# MSS_CTRL register map
Vendor: Texas Instruments
Registers are 32-bit, read-write, no defined reset value unless marked. A register's access mark holds for its fields unless they carry their own. Offsets are as the file gives them; [hi:lo] are bit positions; {n}, {i} and the like mark numbered series; 'fields as' and 'values as' point back to an identical list; <NAME> marks a mode.

## MSS_CTRL (part 2 of 3)
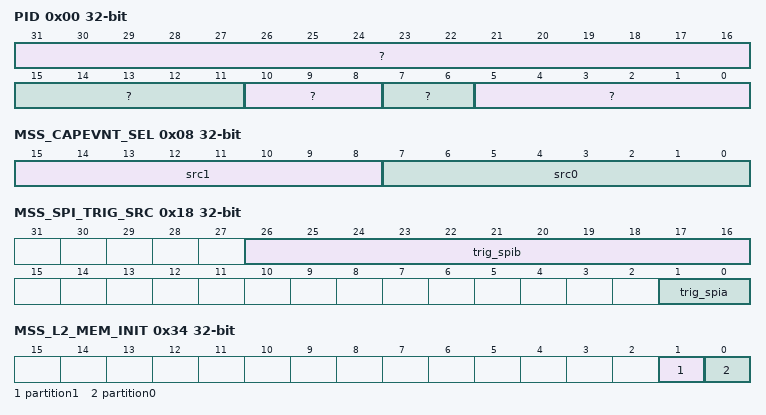
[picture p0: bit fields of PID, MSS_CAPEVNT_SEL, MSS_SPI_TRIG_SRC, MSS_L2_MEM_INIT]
0x00 PID ro
  [31:16] ?, [15:11] ?, [10:8] ?, [7:6] ?, [5:0] ?
0x04 MSS_SW_INT
  [4:0] pulse — write pulse bit field:Write_pulse bit field: writing 1'b1 to each bit will trigger MSS_SW_INT<0-4> respectively to CR5A/B.
0x08 MSS_CAPEVNT_SEL
  [15:8] src1 — Writing a value 'N' will select Nth interrupt from CR5A/B interrupt mapping to trigger CAP-EVENT1 to all MSS_RTIs. Example: writing 8'h0A will select 10th interrupt to trigger CAP-EVENT1 to all MSS_RTIs. (which is MSS_RTIB_INT1)
  [7:0] src0 — Writing a value 'N' will select Nth interrupt from CR5A/B interrupt mapping to trigger CAP-EVENT0 to all MSS_RTIs. Example: writing 8'h0A will select 10th interrupt to trigger CAP-EVENT0 to all MSS_RTIs. (which is MSS_RTIB_INT1)
0x0C MSS_DMA_REQ_SEL
  [31:0] select — Reserved for R&D. Do not touch
0x10 MSS_DMA1_REQ_SEL
  [31:0] select — Reserved for R&D. Do not touch
0x14 MSS_IRQ_REQ_SEL
  [31:0] select — Reserved for R&D. Do not touch
0x18 MSS_SPI_TRIG_SRC
  [26:16] trig_spib — Writing 1'b1 to each bit will trigger MSS_SPIB Trigger<0-10> respectively
  [1:0] trig_spia — Writing 1'b1 to each bit will trigger MSS_SPIA Trigger<0-1> respectively
0x1C MSS_ATCM_MEM_INIT
  [0] mem_init — write pulse bit field:Write_pulse bit field: Writing 1'b1 will start initializing the ATCM banks of CR5A/B. Value in each row is initialized to 0x0C_0000_0000
0x20 MSS_ATCM_MEM_INIT_DONE
  [0] mem_init_done — Rising Edge Capture reg (write 1 to clear): This field will be high once initialization of ATCM banks is finished. Writing '1' would clear the bit.
0x24 MSS_ATCM_MEM_INIT_STATUS ro
  [0] mem_status — 1'b0: No initialization is happening for ATCM banks of CR5A/B 1'b1: Initialization is in progress for ATCM banks of CR5A/B
0x28 MSS_BTCM_MEM_INIT
  [0] mem_init — write pulse bit field:Write_pulse bit field: Writing 1'b1 will start initializing the B0/1TCM banks of CR5A/B
0x2C MSS_BTCM_MEM_INIT_DONE
  [0] mem_init_done — Rising Edge Capture reg (write 1 to clear): This field will be high once initialization of B0/1TCM banks is finished. Writing '1' would clear the bit.
0x30 MSS_BTCM_MEM_INIT_STATUS ro
  [0] mem_status — 1'b0: No initialization is happening for B0/1TCM banks of CR5A/B 1'b1: Initialization is in progress for B0/1TCM banks of CR5A/B
0x34 MSS_L2_MEM_INIT
  [1] partition1 — write pulse bit field:Write_pulse bit field: Writing 1'b1 will start initializing the L2 Bank1. Value in each row is initialized to 0x0
  [0] partition0 — write pulse bit field:Write_pulse bit field: Writing 1'b1 will start initializing the L2 Bank0. Value in each row is initialized to 0x0
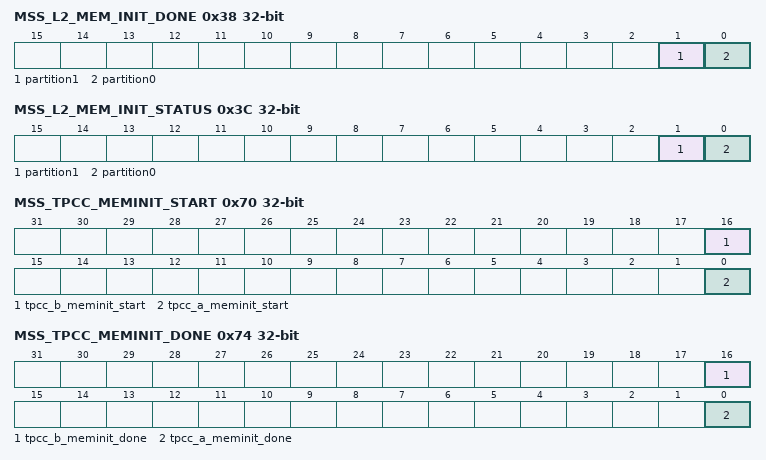
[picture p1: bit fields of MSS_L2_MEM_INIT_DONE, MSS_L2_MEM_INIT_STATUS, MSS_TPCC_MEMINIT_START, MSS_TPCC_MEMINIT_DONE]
0x38 MSS_L2_MEM_INIT_DONE
  [1] partition1 — Rising Edge Capture reg (write 1 to clear): This field will be high once intialization of L2 bank1 is finished. Writing '1' would clear the bit
  [0] partition0 — Rising Edge Capture reg (write 1 to clear): This field will be high once intialization of L2 bank0 is finished. Writing '1' would clear the bit
0x3C MSS_L2_MEM_INIT_STATUS ro
  [1] partition1 — 1'b0: No initialization is happening for L2 bank1 1'b1: Initialization is in progress for L2 bank1
  [0] partition0 — 1'b0: No initialization is happening for L2 bank0 1'b1: Initialization is in progress for L2 bank0
0x40 MSS_MAILBOX_MEM_INIT
  [0] mem0_init — write pulse bit field:Write_pulse bit field: Writing 1'b1 will start initializing the MSS_MBOX. Value in each row is initialized to 0x0
0x44 MSS_MAIlBOX_MEM_INIT_DONE
  [0] mem0_done — Rising Edge Capture reg (write 1 to clear): This field will be high once intialization of MSS_MBOX is finished. Writing '1' would clear the bit
0x48 MSS_MAILBOX_MEM_INIT_STATUS ro
  [0] mem0_status — 1'b0: No initialization is happening for MSS_MBOX 1'b1: Initialization is in progress for MSS_MBOX
0x4C MSS_RETRAM_MEM_INIT
  [0] mem0_init — write pulse bit field:Write_pulse bit field: Writing 1'b1 will start initializing the MSS_RETRAM. Value in each row is initialized to 0x0
0x50 MSS_RETRAM_MEM_INIT_DONE
  [0] mem0_done — Rising Edge Capture reg (write 1 to clear): This field will be high once intialization of MSS_RETRAM is finished. Writing '1' would clear the bit
0x54 MSS_RETRAM_MEM_INIT_STATUS ro
  [0] mem0_status — 1'b0: No initialization is happening for MSS_RETRAM 1'b1: Initialization is in progress for MSS_RETRAM
0x58 MSS_SPIA_MEM_INIT
  [0] mem0_init — write pulse bit field:Write_pulse bit field: Writing 1'b1 will start initializing the MSS_SPIA. Value in each row is initialized to 0x0
0x5C MSS_SPIA_MEM_INIT_DONE
  [0] mem0_done — Rising Edge Capture reg (write 1 to clear): This field will be high once intialization of MSS_SPIA is finished. Writing '1' would clear the bit
0x60 MSS_SPIA_MEM_INIT_STATUS ro
  [0] mem0_status — 1'b0: No initialization is happening for MSS_SPIA 1'b1: Initialization is in progress for MSS_SPIA
0x64 MSS_SPIB_MEM_INIT
  [0] mem0_init — write pulse bit field:Write_pulse bit field: Writing 1'b1 will start initializing the MSS_SPIB. Value in each row is initialized to 0x0
0x68 MSS_SPIB_MEM_INIT_DONE
  [0] mem0_done — Rising Edge Capture reg (write 1 to clear): This field will be high once intialization of MSS_SPIB is finished. Writing '1' would clear the bit
0x6C MSS_SPIB_MEM_INIT_STATUS ro
  [0] mem0_status — 1'b0: No initialization is happening for MSS_SPIB 1'b1: Initialization is in progress for MSS_SPIB
0x70 MSS_TPCC_MEMINIT_START
  [16] tpcc_b_meminit_start — write pulse bit field:Write_pulse bit field: Writing 1'b1 will start initializing the MSS_TPCCB
  [0] tpcc_a_meminit_start — write pulse bit field:Write_pulse bit field: Writing 1'b1 will start initializing the MSS_TPCCA
0x74 MSS_TPCC_MEMINIT_DONE
  [16] tpcc_b_meminit_done — Rising Edge Capture reg (write 1 to clear): This field will be high once intialization of MSS_TPCCB is finished. Writing '1' would clear the bit
  [0] tpcc_a_meminit_done — Rising Edge Capture reg (write 1 to clear): This field will be high once intialization of MSS_TPCCA is finished. Writing '1' would clear the bit
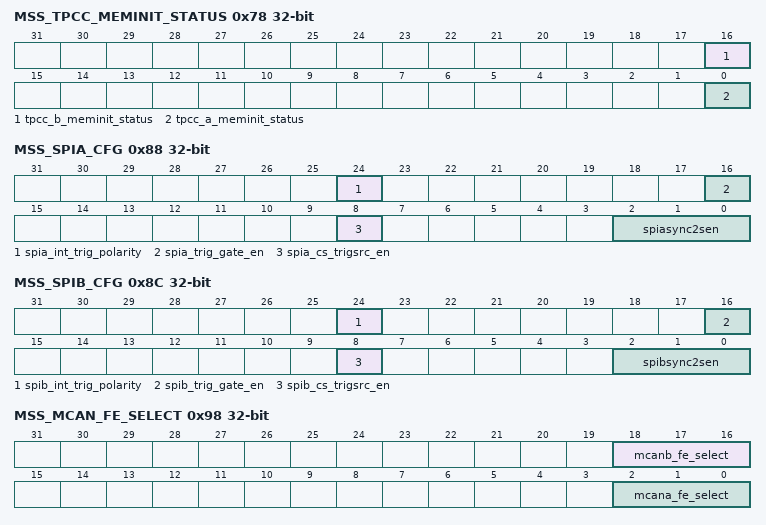
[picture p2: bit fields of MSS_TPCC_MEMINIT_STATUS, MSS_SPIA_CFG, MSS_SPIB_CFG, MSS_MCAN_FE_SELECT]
0x78 MSS_TPCC_MEMINIT_STATUS ro
  [16] tpcc_b_meminit_status — 1'b0: No initialization is happening for MSS_TPCCA 1'b1: Initialization is in progress for MSS_TPCCB
  [0] tpcc_a_meminit_status — 1'b0: No initialization is happening for MSS_TPCCA 1'b1: Initialization is in progress for MSS_TPCCB
0x7C MSS_GPADC_MEM_INIT
  [0] mem0_init — write pulse bit field:Write_pulse bit field: Writing 1'b1 will start initializing the MSS_GPADC_DATA_MEM. Value in each row is initialized to 0x00_0000_03FF
0x80 MSS_GPADC_MEM_INIT_DONE
  [0] mem0_done — Rising Edge Capture reg (write 1 to clear): This field will be high once intialization of MSS_GPADC_DATA_MEM is finished. Writing '1' would clear the bit
0x84 MSS_GPADC_MEM_INIT_STATUS ro
  [0] mem0_status — 1'b0: No initialization is happening for MSS_GPADC_DATA_MEM 1'b1: Initialization is in progress for MSS_GPADC_DATA_MEM
0x88 MSS_SPIA_CFG
  [24] spia_int_trig_polarity — SPIA trigger source polarity select. 0 - Polarity 0, 1 -Polarity 1
  [16] spia_trig_gate_en — When set the TRIGGER s are un-gated only when chip-select is active
  [8] spia_cs_trigsrc_en — MIBSPIB CS Trigger SRC enable 1 : Use CS as trigger source
  [2:0] spiasync2sen — Donot touch the field. Used as Tie-off for IP-config.
0x8C MSS_SPIB_CFG
  [24] spib_int_trig_polarity — SPIB trigger source polarity select. 0 - Polarity 0, 1 -Polarity 1
  [16] spib_trig_gate_en — When set the TRIGGER s are un-gated only when chip-select is active
  [8] spib_cs_trigsrc_en — MIBSPIB CS Trigger SRC enable 1 : Use CS as trigger source
  [2:0] spibsync2sen — Donot touch the field. Used as Tie-off for IP-config.
0x90 MSS_EPWM_CFG
  [31:0] epwm_config — bit0: SW syncin for EPWM1 bit1: SW syncin for EPWM2 bit2: SW syncin for EPWM3 bit8:9 : select bits for EPWM1 '0' : external syncin '1' : reserved '2' : sw syncin '3' : reserved bit10:11 : select bits for EPWM2 '0' : external syncin '1' : chained from EPWM1 '2' : sw syncin '3' : reserved bit12:13 : select bits for EPWM3 '0' : external syncin '1' : chained from EPWM2 '2' : sw syncin '3' : reserved bit24:TBCLKEN for EPWM1 bit25:TBCLKEN for EPWM2 bit26:TBCLKEN for EPWM3
0x94 MSS_GIO_CFG
  [31:0] gio_config — bit0 : writing '1' will slect negedge for pulse generation of GIO_PAD_INT0 to IRQ bit1 : writing '1' will slect negedge for pulse generation of GIO_PAD_INT1to IRQ bit2: writing '1' will slect negedge for pulse generation of GIO_PAD_INT2 to IRQ bit3 : writing '1' will slect negedge for pulse generation of GIO_PAD_INT3 to IRQ bit4 : writing '1' will slect negedge for pulse generation of GIO_PAD_INT4 to IRQ bit5 : writing '1' will slect negedge for pulse generation of GIO_PAD_INT5 to IRQ bit6 : writing '1' will slect negedge for pulse generation of GIO_PAD_INT6 to IRQ bit7 : writing '1' will slect negedge for pulse generation of GIO_PAD_INT7 to IRQ
0x98 MSS_MCAN_FE_SELECT
  [18:16] mcanb_fe_select — writing a value'N' would select Nth filter interrupt combination for hwa_cm4 interrupt and also HW_SYNC_IN Example: writing 3'd<1-7> selects MSS_MCANB_FE_INT<1-7> respectively
  [2:0] mcana_fe_select — writing a value'N' would select Nth filter interrupt combination for hwa_cm4 interrupt and also HW_SYNC_IN Example: writing 3'd<1-7> would select MSS_MCANA_FE_INT<1-7> respectively
0x9C HW_SPARE_REG1
  [31:0] NU — Resereved for R&D
0xA0 MSS_MCANA_INT_CLR
  [31:0] mcan_int_clr — Interrupt Clear for 32 MCANSS TX DMA interrupts. Writing 1'b1 to bit<0-31> clears interrupt source <0-31> respectively in MCANA
0xA4 MSS_MCANA_INT_MASK
  [31:0] mcan_int_mask — Interrupt Mask for 32 MCANSS TX DMA interrupts. Writing 1'b1 to bit<0-31> masks interrupt source <0-31> respectively in MCANA
0xA8 MSS_MCANA_INT_STAT ro
  [31:0] mcan_int_status — Interrupt status for 32 MCANSS TX DMA interrupts. 1'b1 in bit<0-31> gives pending status for interrupt <0-31> respectively in MCANA
0xAC HW_SPARE_REG2
  [31:0] NU — Resereved for R&D
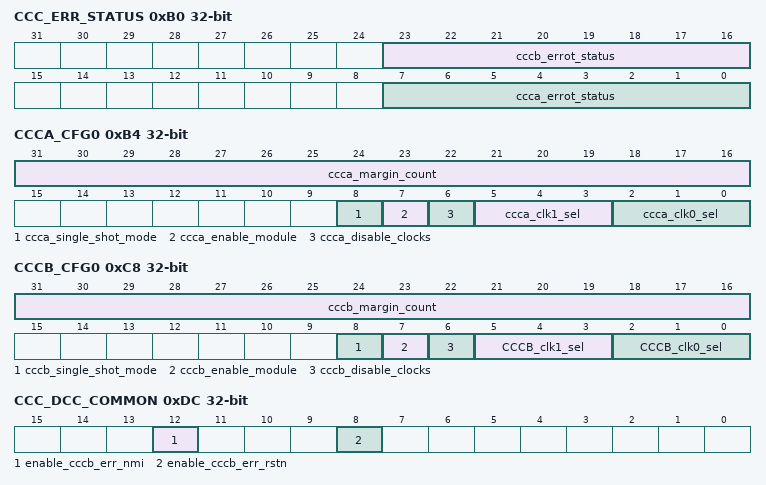
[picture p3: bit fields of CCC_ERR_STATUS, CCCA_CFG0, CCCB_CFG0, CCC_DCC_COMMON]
0xB0 CCC_ERR_STATUS ro
  [23:16] cccb_errot_status — CCCB Error Status (for Debug) {3'd0, counter_error, counter_done, timeout_error, counter_error, counter_done}
  [7:0] ccca_errot_status — CCCA Error Status (for Debug) {3'd0, counter_error, counter_done, timeout_error, counter_error, counter_done}
0xB4 CCCA_CFG0
  [31:16] ccca_margin_count — Margin value for clock comparison in terms of counter1 clock.CCC error will not be generated if counter1 counter value is within count1_expected_val +/- MARGIN_COUNT
  [8] ccca_single_shot_mode — 1: Single shot mode 0: Continuous mode
  [7] ccca_enable_module — 1'b1: Enables CCCA 1'b0: Disables CCCA
  [6] ccca_disable_clocks — 1: Clock gated to counter0 and counter1 0: Normal mode
  [5:3] ccca_clk1_sel — Selection for Clock 1 0: Select clock0_src0 as source for counter1 1: Select clock0_src1 as source for counter1 2: Select clock0_src2 as source for counter1 ... 7: Select clock0_src7 as source for counter1
  [2:0] ccca_clk0_sel — Selection for Clock 0 0: Select clock0_src0 as source for counter0 1: Select clock0_src1 as source for counter0 2: Select clock0_src2 as source for counter0 ... 7: Select clock0_src7 as source for counter0
0xB8 CCCA_CFG1
  [31:0] ccca_cfg — count0_expiry_val Counter 1 is compared for count1_expected_val +/- MARGIN_COUNT when counter0 expires after counting down from count0_expiry_val to 0
0xBC CCCA_CFG2
  [31:0] ccca_cfg — count1_expected_val Expected value of counter 1 when counter 0 expires after counting down from count0_expiry value
0xC0 CCCA_CFG3
  [31:0] ccca_cfg — Timeout Error Counter value in counter1 clock
0xC4 CCCA_CNTVAL ro
  [31:0] ccca_cfg — count1_val_out Real time value of counter1
0xC8 CCCB_CFG0
  [31:16] cccb_margin_count — Margin value for clock comparison in terms of counter1 clock.CCC error will not be generated if counter1 counter value is within count1_expected_val +/- MARGIN_COUNT
  [8] cccb_single_shot_mode — 1: Single shot mode 0: Continuous mode
  [7] cccb_enable_module — 1'b1: Enables CCCB 1'b0: Disables CCCB
  [6] cccb_disable_clocks — 1: Clock gated to counter0 and counter1 0: Normal mode
  [5:3] CCCB_clk1_sel — Selection for Clock 1 0: Select clock0_src0 as source for counter1 1: Select clock0_src1 as source for counter1 2: Select clock0_src2 as source for counter1 ... 7: Select clock0_src7 as source for counter1
  [2:0] CCCB_clk0_sel — Selection for Clock 0 0: Select clock0_src0 as source for counter0 1: Select clock0_src1 as source for counter0 2: Select clock0_src2 as source for counter0 ... 7: Select clock0_src7 as source for counter0
0xCC CCCB_CFG1
  [31:0] cccb_cfg — count0_expiry_val Counter 1 is compared for count1_expected_val +/- MARGIN_COUNT when counter0 expires after counting down from count0_expiry_val to 0
0xD0 CCCB_CFG2
  [31:0] cccb_cfg — count1_expected_val Expected value of counter 1 when counter 0 expires after counting down from count0_expiry value
0xD4 CCCB_CFG3
  [31:0] cccb_cfg — Timeout Error Counter value in counter1 clock
0xD8 CCCB_CNTVAL ro
  [31:0] cccb_cfg — count1_val_out Real time value of counter1
0xDC CCC_DCC_COMMON
  [12] enable_cccb_err_nmi — 1'b0:Enable CCCB error to generate NMI. 1'b1:disables CCCB error to generate NMI.
  [8] enable_cccb_err_rstn — 1'b0: Enable CCCB error to generate WD restn. 1'b1: disables CCCB error to generate WD restn.
0xE0 R5_GLOBAL_CONFIG
  [0] teinit — Exception handling state at reset. 0-ARM 1-Thumb
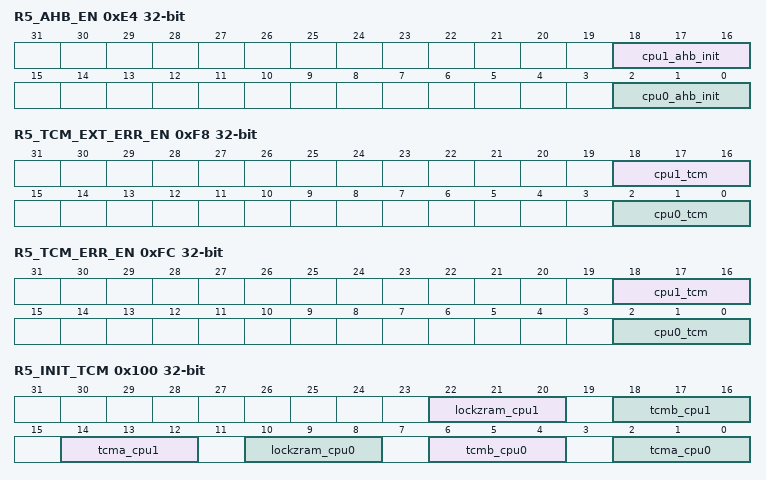
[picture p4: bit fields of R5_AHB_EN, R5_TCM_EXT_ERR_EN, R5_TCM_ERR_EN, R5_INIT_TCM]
0xE4 R5_AHB_EN
  [18:16] cpu1_ahb_init — Ti internal Register. Modifying this register is not recommended Signal decides whehter ahb interface is enabled or not.
  [2:0] cpu0_ahb_init — Ti internal Register. Modifying this register is not recommended Signal decides whehter ahb interface is enabled or not.
0xE8 R5A_AHB_BASE
  [19:0] ahb_base — Ti internal Register. Modifying this register is not recommended Decides the base address of ahb region
0xEC R5A_AHB_SIZE
  [4:0] ahb_size — Ti internal Register. Modifying this register is not recommended Code for selecting size for ahb. b00011 4KB b00100 8KB b00101 16KB b00110 32KB b00111 64KB b01000 128KB b01001 256KB b01010 512KB b01011 1MB b01100 2MB b01101 4MB b01110 8MB b01111 16MB b10000 32MB b10001 64MB b10010 128MB b10011 256MB b10100 512MB b10101 1GB b10110 2GB b10111 4GB
0xF0 R5B_AHB_BASE
  fields as R5A_AHB_BASE
0xF4 R5B_AHB_SIZE
  fields as R5A_AHB_SIZE
0xF8 R5_TCM_EXT_ERR_EN
  [18:16] cpu1_tcm — Ti internal Register. Modifying this register is not recommended TCMs external error enable. Tie each bit high to enable the external error signal for each TCM at reset
  [2:0] cpu0_tcm — Ti internal Register. Modifying this register is not recommended TCMs external error enable. Tie each bit high to enable the external error signal for each TCM at reset
0xFC R5_TCM_ERR_EN
  [18:16] cpu1_tcm — Ti internal Register. Modifying this register is not recommended TCMs ECC check enable. Tie each bit high to enable ECC checking on appropraite TCM
  [2:0] cpu0_tcm — Ti internal Register. Modifying this register is not recommended TCMs ECC check enable. Tie each bit high to enable ECC checking on appropraite TCM
0x100 R5_INIT_TCM
  [22:20] lockzram_cpu1 — Ti internal Register. Modifying this register is not recommended When HIGH ATCM base address at reset is 0x0 when LOW BTCM base address at reset is 0x0
  [18:16] tcmb_cpu1 — Ti internal Register. Modifying this register is not recommended When HIGH enables BTCM interface out of reset
  [14:12] tcma_cpu1 — Ti internal Register. Modifying this register is not recommended When HIGH enables ATCM interface out of reset
  [10:8] lockzram_cpu0 — Ti internal Register. Modifying this register is not recommended When HIGH ATCM base address at reset is 0x0 when LOW BTCM base address at reset is 0x0
  [6:4] tcmb_cpu0 — Ti internal Register. Modifying this register is not recommended When HIGH enables BTCM interface out of reset
  [2:0] tcma_cpu0 — Ti internal Register. Modifying this register is not recommended When HIGH enables ATCM interface out of reset
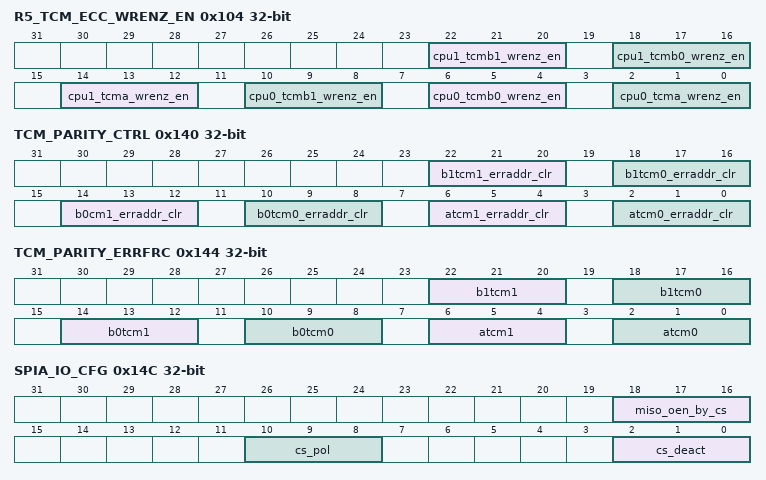
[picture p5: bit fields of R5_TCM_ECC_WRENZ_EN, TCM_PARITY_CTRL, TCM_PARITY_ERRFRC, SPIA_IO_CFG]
0x104 R5_TCM_ECC_WRENZ_EN
  [22:20] cpu1_tcmb1_wrenz_en — writing '000' blocks the writes to ECC-bits of TCMB0-RAM of CR5B. Writing '111' unblocks the writes to ECC-bits of TCMB1-RAM of CR5B
  [18:16] cpu1_tcmb0_wrenz_en — writing '000' blocks the writes to ECC-bits of TCMB0-RAM of CR5B. Writing '111' unblocks the writes to ECC-bits of TCMB0-RAM of CR5B
  [14:12] cpu1_tcma_wrenz_en — writing '000' blocks the writes to ECC-bits of TCMA-RAM of CR5B. Writing '111' unblocks the writes to ECC-bits of TCMA-RAM of CR5B
  [10:8] cpu0_tcmb1_wrenz_en — writing '000' blocks the writes to ECC-bits of TCMB0-RAM of CR5A. Writing '111' unblocks the writes to ECC-bits of TCMB1-RAM of CR5A
  [6:4] cpu0_tcmb0_wrenz_en — writing '000' blocks the writes to ECC-bits of TCMB0-RAM of CR5A. Writing '111' unblocks the writes to ECC-bits of TCMB0-RAM of CR5A
  [2:0] cpu0_tcma_wrenz_en — writing '000' blocks the writes to ECC-bits of TCMA-RAM of CR5A. Writing '111' unblocks the writes to ECC-bits of TCMA-RAM of CR5A
{0x108+4i} ESM_GATING{i} (i=0..3)
  [31:0] esm_gating — bit3:0 : writing '000' will ungate the ESM_GRP2_ERROR_{8i} bit7:4 : writing '000' will ungate the ESM_GRP2_ERROR_{8i+1} bit31:28 : writing '000' will ungate the ESM_GRP2_ERROR_{8i+7}
{0x108+4i} ESM_GATING{i} (i=4..7)
  [31:0] esm_gating — bit3:0 : writing '000' will ungate the ESM_GRP3_ERROR_{8i-32} bit7:4 : writing '000' will ungate the ESM_GRP3_ERROR_{8i-31} bit31:28 : writing '000' will ungate the ESM_GRP3_ERROR_{8i-25}
0x128 ERR_PARITY_ATCM0 ro
  [19:0] addr — Address lathched when parity error is occurred for ATCM of CR5A
0x12C ERR_PARITY_ATCM1 ro
  [19:0] addr — Address lathched when parity error is occurred for ATCM of CR5B
0x130 ERR_PARITY_B0TCM0 ro
  [19:0] addr — Address lathched when parity error is occurred for B0TCM of CR5A
0x134 ERR_PARITY_B0TCM1 ro
  [19:0] addr — Address lathched when parity error is occurred for B0TCM of CR5B
0x138 ERR_PARITY_B1TCM0 ro
  [19:0] addr — Address lathched when parity error is occurred for B1TCM of CR5A
0x13C ERR_PARITY_B1TCM1 ro
  [19:0] addr — Address lathched when parity error is occurred for B1TCM of CR5B
0x140 TCM_PARITY_CTRL
  [22:20] b1tcm1_erraddr_clr — Write pulse bit field: writing 3'b111 clears the Address latched after parity error for B1TCM of CR5B
  [18:16] b1tcm0_erraddr_clr — Write pulse bit field: writing 3'b111 clears the Address latched after parity error for B1TCM of CR5A
  [14:12] b0cm1_erraddr_clr — Write pulse bit field: writing 3'b111 clears the Address latched after parity error for B0TCM of CR5B
  [10:8] b0tcm0_erraddr_clr — Write pulse bit field: writing 3'b111 clears the Address latched after parity error for B0TCM of CR5A
  [6:4] atcm1_erraddr_clr — Write pulse bit field: writing 3'b111 clears the Address latched after parity error for ATCM of CR5B
  [2:0] atcm0_erraddr_clr — write pulse bit field:Pulse bit-field writing 3'b111 clears the Address latched after parity error for ATCM of CR5A
0x144 TCM_PARITY_ERRFRC
  [22:20] b1tcm1 — Write pulse bit field: writing 3'b111 forces a parity error for B1TCM of CR5B
  [18:16] b1tcm0 — Write pulse bit field: writing 3'b111 forces a parity error for B1TCM of CR5A
  [14:12] b0tcm1 — Write pulse bit field: writing 3'b111 forces a parity error for B0TCM of CR5B
  [10:8] b0tcm0 — Write pulse bit field: writing 3'b111 forces a parity error for B0TCM of CR5A
  [6:4] atcm1 — Write pulse bit field: writing 3'b111 forces a parity error for ATCM of CR5B
  [2:0] atcm0 — Write pulse bit field: writing 3'b111 forces a parity error for ATCM of CR5A
0x148 HW_SPARE_REG3
  [31:0] NU — Resereved for R&D
0x14C SPIA_IO_CFG
  [18:16] miso_oen_by_cs — MIBSPIA MISO OE_N Control based on Chip selectCS-applicable in slave mode 1:MISO OEN controlled based on CS.When CS is inactive OE_N=1 0:MISO OEN controlled by IP
  [10:8] cs_pol — MIBSPIA CS polarity-slave mode 1: Active high 0:Active low
  [2:0] cs_deact — 1 : MIBSPIA External chip select is overridden with the value of MIBSPIA CS polarity-slave mode
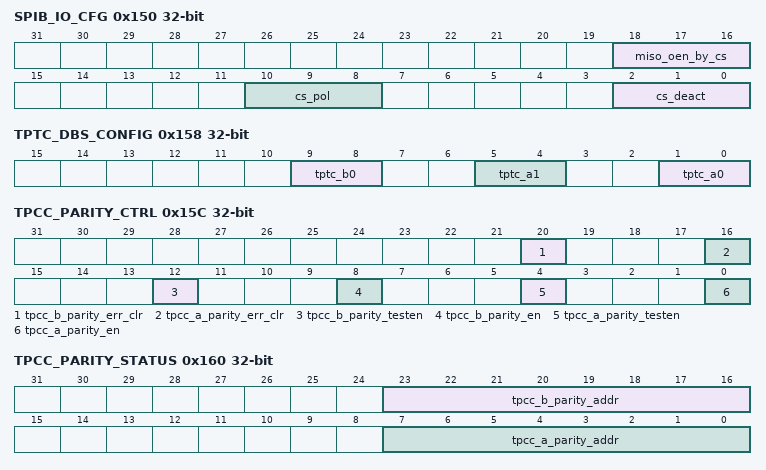
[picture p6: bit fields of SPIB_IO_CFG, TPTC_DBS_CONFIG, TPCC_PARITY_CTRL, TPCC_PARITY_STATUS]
0x150 SPIB_IO_CFG
  [18:16] miso_oen_by_cs — MIBSPIB MISO OE_N Control based on Chip selectCS-applicable in slave mode 1:MISO OEN controlled based on CS.When CS is inactive OE_N=1 0:MISO OEN controlled by IP
  [10:8] cs_pol — MIBSPIB CS polarity-slave mode 1: Active high 0:Active low
  [2:0] cs_deact — 1 : MIBSPIB External chip select is overridden with the value of MIBSPIB CS polarity-slave mode
0x154 SPI_HOST_IRQ
  [2:0] host_irq
0x158 TPTC_DBS_CONFIG
  [9:8] tptc_b0 — Default burst size tieoff value for TPTC_B0
  [5:4] tptc_a1 — Default burst size tieoff value for TPTC_A1
  [1:0] tptc_a0 — Default burst size tieoff value for TPTC_A0
0x15C TPCC_PARITY_CTRL
  [20] tpcc_b_parity_err_clr — Write pulse bit field: parity clear bit. Writing 1'b1 will clear the tpcc_b_parity_addr
  [16] tpcc_a_parity_err_clr — Write pulse bit field: parity clear bit. Writing 1'b1 will clear the tpcc_a_parity_addr
  [12] tpcc_b_parity_testen — parity test enable for tpcc b
  [8] tpcc_b_parity_en — parity en for tpcc b
  [4] tpcc_a_parity_testen — parity test enable for tpcc a
  [0] tpcc_a_parity_en — writing 1'b1 enables parity for TPCC_A
0x160 TPCC_PARITY_STATUS ro
  [23:16] tpcc_b_parity_addr — address where parity error happened for tpccb
  [7:0] tpcc_a_parity_addr — address where parity error happened for tpcca
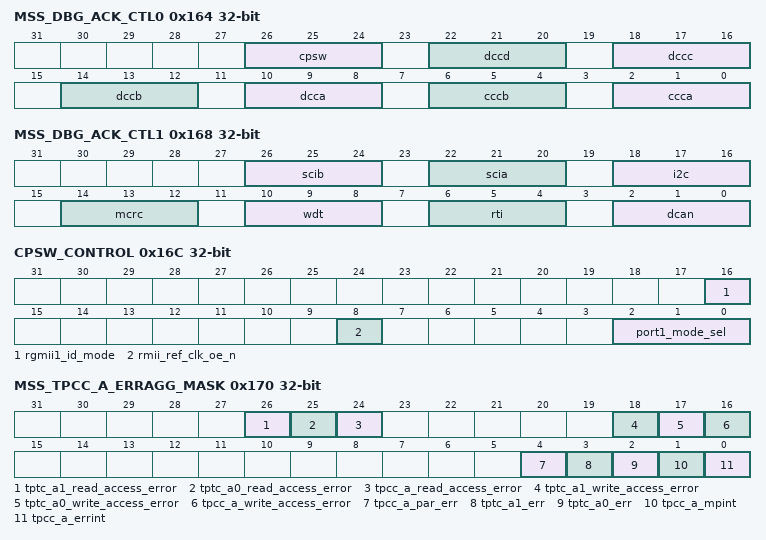
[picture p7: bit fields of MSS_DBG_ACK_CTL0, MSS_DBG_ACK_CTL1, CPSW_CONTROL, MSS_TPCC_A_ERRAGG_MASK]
0x164 MSS_DBG_ACK_CTL0
  [26:24] cpsw — Enable Suspend control for the peripheral. 0 :Peripheral not suspended along with processor 1: Peripehal Suspended along with procesor
  [22:20] dccd — Enable Suspend control for the peripheral. 0 :Peripheral not suspended along with processor 1: Peripehal Suspended along with procesor
  [18:16] dccc — Enable Suspend control for the peripheral. 0 :Peripheral not suspended along with processor 1: Peripehal Suspended along with procesor
  [14:12] dccb — Enable Suspend control for the peripheral. 0 :Peripheral not suspended along with processor 1: Peripehal Suspended along with procesor
  [10:8] dcca — Enable Suspend control for the peripheral. 0 :Peripheral not suspended along with processor 1: Peripehal Suspended along with procesor
  [6:4] cccb — Enable Suspend control for the peripheral. 0 :Peripheral not suspended along with processor 1: Peripehal Suspended along with procesor
  [2:0] ccca — Enable Suspend control for the peripheral. 0 :Peripheral not suspended along with processor 1: Peripehal Suspended along with procesor
0x168 MSS_DBG_ACK_CTL1
  [26:24] scib — Enable Suspend control for the peripheral. 0 :Peripheral not suspended along with processor 1: Peripehal Suspended along with procesor
  [22:20] scia — Enable Suspend control for the peripheral. 0 :Peripheral not suspended along with processor 1: Peripehal Suspended along with procesor
  [18:16] i2c — Enable Suspend control for the peripheral. 0 :Peripheral not suspended along with processor 1: Peripehal Suspended along with procesor
  [14:12] mcrc — Enable Suspend control for the peripheral. 0 :Peripheral not suspended along with processor 1: Peripehal Suspended along with procesor
  [10:8] wdt — Enable Suspend control for the peripheral. 0 :Peripheral not suspended along with processor 1: Peripehal Suspended along with procesor
  [6:4] rti — Enable Suspend control for the peripheral. 0 :Peripheral not suspended along with processor 1: Peripehal Suspended along with procesor
  [2:0] dcan — Enable Suspend control for the peripheral. 0 :Peripheral not suspended along with processor 1: Peripehal Suspended along with procesor
0x16C CPSW_CONTROL
  [16] rgmii1_id_mode — writing 1'b1 would disable the internal clock delays. And those delays need to be handled on board.
  [8] rmii_ref_clk_oe_n — To select the rmii_ref_clk from PAD or from MSS_RCM. 0: clock will be from mss_rcm through IO internal loopback 1: will be from
  [2:0] port1_mode_sel — Port 1 Interface 00 = GMII/MII 01 = RMII 10 = RGMII 11 = Not Supported
0x170 MSS_TPCC_A_ERRAGG_MASK
  [26] tptc_a1_read_access_error — Mask Error from MSS_TPTC_A1 to aggregated Error MSS_TPCC_A_ERRAGG 1 : Error is Masked 0 : Error is Unmasked
  [25] tptc_a0_read_access_error — Mask Error from MSS_TPTC_A0 to aggregated Error MSS_TPCC_A_ERRAGG 1 : Error is Masked 0 : Error is Unmasked
  [24] tpcc_a_read_access_error — Mask Error from MSS_TPCC_A to aggregated Error MSS_TPCC_A_ERRAGG 1 : Error is Masked 0 : Error is Unmasked
  [18] tptc_a1_write_access_error — Mask Error from MSS_TPTC_A1 to aggregated Error MSS_TPCC_A_ERRAGG 1 : Error is Masked 0 : Error is Unmasked
  [17] tptc_a0_write_access_error — Mask Error from MSS_TPTC_A0 to aggregated Error MSS_TPCC_A_ERRAGG 1 : Error is Masked 0 : Error is Unmasked
  [16] tpcc_a_write_access_error — Mask Error from MSS_TPCC_A to aggregated Error MSS_TPCC_A_ERRAGG 1 : Error is Masked 0 : Error is Unmasked
  [4] tpcc_a_par_err — Mask Error from MSS_TPCC_A to aggregated Error MSS_TPCC_A_ERRAGG 1 : Error is Masked 0 : Error is Unmasked
  [3] tptc_a1_err — Mask Error from MSS_TPTC_A1 to aggregated Error MSS_TPCC_A_ERRAGG 1 : Error is Masked 0 : Error is Unmasked
  [2] tptc_a0_err — Mask Error from MSS_TPTC_A0 to aggregated Error MSS_TPCC_A_ERRAGG 1 : Error is Masked 0 : Error is Unmasked
  [1] tpcc_a_mpint — Mask Error from MSS_TPCC_A to aggregated Error MSS_TPCC_A_ERRAGG 1 : Error is Masked 0 : Error is Unmasked
  [0] tpcc_a_errint — Mask Error from MSS_TPCC_A to aggregated Error MSS_TPCC_A_ERRAGG 1 : Error is Masked 0 : Error is Unmasked
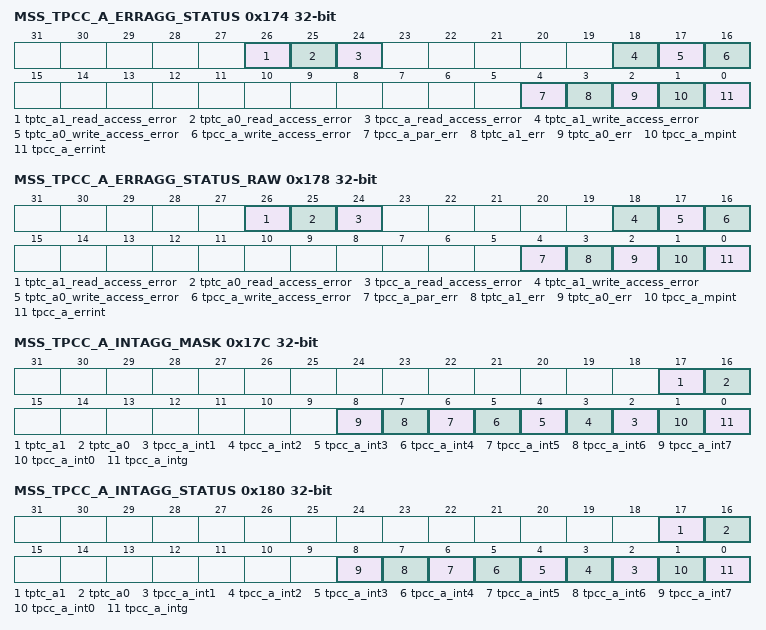
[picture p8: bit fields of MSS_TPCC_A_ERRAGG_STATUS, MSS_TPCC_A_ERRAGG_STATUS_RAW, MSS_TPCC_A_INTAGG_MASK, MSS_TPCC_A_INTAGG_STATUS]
0x174 MSS_TPCC_A_ERRAGG_STATUS
  [26] tptc_a1_read_access_error — Rising Edge Capture reg (write 1 to clear): Status of Error from MSS_TPTC_A1. Set only if Interupt is unmasked in MSS_TPCC_A_ERRAGG_MASK Wrie 0x1 to clear this Error.
  [25] tptc_a0_read_access_error — Rising Edge Capture reg (write 1 to clear): Status of Error from MSS_TPTC_A0. Set only if Interupt is unmasked in MSS_TPCC_A_ERRAGG_MASK Wrie 0x1 to clear this Error.
  [24] tpcc_a_read_access_error — Rising Edge Capture reg (write 1 to clear): Status of Error from MSS_TPCC_A. Set only if Interupt is unmasked in MSS_TPCC_A_ERRAGG_MASK Wrie 0x1 to clear this Error.
  [18] tptc_a1_write_access_error — Rising Edge Capture reg (write 1 to clear): Status of Error from MSS_TPTC_A1. Set only if Interupt is unmasked in MSS_TPCC_A_ERRAGG_MASK Wrie 0x1 to clear this Error.
  [17] tptc_a0_write_access_error — Rising Edge Capture reg (write 1 to clear): Status of Error from MSS_TPTC_A0. Set only if Interupt is unmasked in MSS_TPCC_A_ERRAGG_MASK Wrie 0x1 to clear this Error.
  [16] tpcc_a_write_access_error — Rising Edge Capture reg (write 1 to clear): Status of Error from MSS_TPCC_A. Set only if Interupt is unmasked in MSS_TPCC_A_ERRAGG_MASK Wrie 0x1 to clear this Error.
  [4] tpcc_a_par_err — Rising Edge Capture reg (write 1 to clear): Status of Error from MSS_TPCC_A. Set only if Interupt is unmasked in MSS_TPCC_A_ERRAGG_MASK Wrie 0x1 to clear this Error.
  [3] tptc_a1_err — Rising Edge Capture reg (write 1 to clear): Status of Error from MSS_TPTC_A1. Set only if Interupt is unmasked in MSS_TPCC_A_ERRAGG_MASK Wrie 0x1 to clear this Error.
  [2] tptc_a0_err — Rising Edge Capture reg (write 1 to clear): Status of Error from MSS_TPTC_A0. Set only if Interupt is unmasked in MSS_TPCC_A_ERRAGG_MASK Wrie 0x1 to clear this Error.
  [1] tpcc_a_mpint — Rising Edge Capture reg (write 1 to clear): Status of Error from MSS_TPCC_A. Set only if Interupt is unmasked in MSS_TPCC_A_ERRAGG_MASK Wrie 0x1 to clear this Error.
  [0] tpcc_a_errint — Rising Edge Capture reg (write 1 to clear): Status of Error from MSS_TPCC_A. Set only if Interupt is unmasked in MSS_TPCC_A_ERRAGG_MASK Wrie 0x1 to clear this Error.
0x178 MSS_TPCC_A_ERRAGG_STATUS_RAW
  [26] tptc_a1_read_access_error — Rising Edge Capture reg (write 1 to clear): Raw Status of Error from MSS_TPTC_A1. Set irrespective if the Interupt is masked or unmasked in MSS_TPCC_A_ERRAGG_MASK
  [25] tptc_a0_read_access_error — Rising Edge Capture reg (write 1 to clear): Raw Status of Error from MSS_TPTC_A0. Set irrespective if the Interupt is masked or unmasked in MSS_TPCC_A_ERRAGG_MASK
  [24] tpcc_a_read_access_error — Rising Edge Capture reg (write 1 to clear): Raw Status of Error from MSS_TPCC_A. Set irrespective if the Interupt is masked or unmasked in MSS_TPCC_A_ERRAGG_MASK
  [18] tptc_a1_write_access_error — Rising Edge Capture reg (write 1 to clear): Raw Status of Error from MSS_TPTC_A1. Set irrespective if the Interupt is masked or unmasked in MSS_TPCC_A_ERRAGG_MASK
  [17] tptc_a0_write_access_error — Rising Edge Capture reg (write 1 to clear): Raw Status of Error from MSS_TPTC_A0. Set irrespective if the Interupt is masked or unmasked in MSS_TPCC_A_ERRAGG_MASK
  [16] tpcc_a_write_access_error — Rising Edge Capture reg (write 1 to clear): Raw Status of Error from MSS_TPCC_A. Set irrespective if the Interupt is masked or unmasked in MSS_TPCC_A_ERRAGG_MASK
  [4] tpcc_a_par_err — Rising Edge Capture reg (write 1 to clear): Raw Status of Error from MSS_TPCC_A. Set irrespective if the Interupt is masked or unmasked in MSS_TPCC_A_ERRAGG_MASK
  [3] tptc_a1_err — Rising Edge Capture reg (write 1 to clear): Raw Status of Error from MSS_TPTC_A1. Set irrespective if the Interupt is masked or unmasked in MSS_TPCC_A_ERRAGG_MASK
  [2] tptc_a0_err — Rising Edge Capture reg (write 1 to clear): Raw Status of Error from MSS_TPTC_A0. Set irrespective if the Interupt is masked or unmasked in MSS_TPCC_A_ERRAGG_MASK
  [1] tpcc_a_mpint — Rising Edge Capture reg (write 1 to clear): Raw Status of Error from MSS_TPCC_A. Set irrespective if the Interupt is masked or unmasked in MSS_TPCC_A_ERRAGG_MASK
  [0] tpcc_a_errint — Rising Edge Capture reg (write 1 to clear): Raw Status of Error from MSS_TPCC_A. Set irrespective if the Interupt is masked or unmasked in MSS_TPCC_A_ERRAGG_MASK
0x17C MSS_TPCC_A_INTAGG_MASK
  [17] tptc_a1 — Mask Interrupt from TPTC A1 to aggregated Interrupt MSS_TPCC_A_INTAGG 1 : Interrupt is Masked 0 : Interrupt is Unmasked
  [16] tptc_a0 — Mask Interrupt from TPTC A0 to aggregated Interrupt MSS_TPCC_A_INTAGG 1 : Interrupt is Masked 0 : Interrupt is Unmasked
  [n+1] tpcc_a_int{n} (n=1..7) — Mask Interrupt from MSS_TPCC_A to aggregated Interrupt MSS_TPCC_A_INTAGG 1 : Interrupt is Masked 0 : Interrupt is Unmasked
  [1] tpcc_a_int0 — Mask Interrupt from TPCC A to aggregated Interrupt MSS_TPCC_A_INTAGG 1 : Interrupt is Masked 0 : Interrupt is Unmasked
  [0] tpcc_a_intg — Mask Interrupt from MSS_TPCC_A to aggregated Interrupt MSS_TPCC_A_INTAGG 1 : Interrupt is Masked 0 : Interrupt is Unmasked
0x180 MSS_TPCC_A_INTAGG_STATUS
  [17] tptc_a1 — Rising Edge Capture reg (write 1 to clear): Status of Interrupt from TPTC A1. Set only if Interupt is unmasked in MSS_TPCC_A_INTAGG_MASK Wrie 0x1 to clear this interrupt.
  [16] tptc_a0 — Rising Edge Capture reg (write 1 to clear): Status of Interrupt from TPTC A0. Set only if Interupt is unmasked in MSS_TPCC_A_INTAGG_MASK Wrie 0x1 to clear this interrupt.
  [n+1] tpcc_a_int{n} (n=1..7) — Rising Edge Capture reg (write 1 to clear): Status of Interrupt from MSS_TPCC_A. Set only if Interupt is unmasked in MSS_TPCC_A_INTAGG_MASK Wrie 0x1 to clear this interrupt.
  [1] tpcc_a_int0 — Rising Edge Capture reg (write 1 to clear): Status of Interrupt from TPCC A Set only if Interupt is unmasked in MSS_TPCC_A_INTAGG_MASK Wrie 0x1 to clear this interrupt.
  [0] tpcc_a_intg — Rising Edge Capture reg (write 1 to clear): Status of Interrupt from MSS_TPCC_A. Set only if Interupt is unmasked in MSS_TPCC_A_INTAGG_MASK Wrie 0x1 to clear this interrupt.
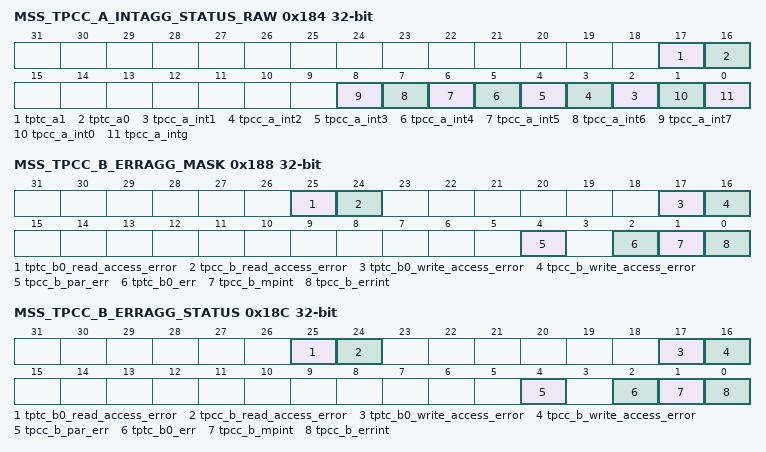
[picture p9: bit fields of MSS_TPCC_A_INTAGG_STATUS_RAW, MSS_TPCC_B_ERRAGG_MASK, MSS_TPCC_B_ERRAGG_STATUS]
0x184 MSS_TPCC_A_INTAGG_STATUS_RAW
  [17] tptc_a1 — Rising Edge Capture reg (write 1 to clear): Raw Status of Interrupt from TPTC A1. Set irrespective if the Interupt is masked or unmasked in MSS_TPCC_A_INTAGG_MASK
  [16] tptc_a0 — Rising Edge Capture reg (write 1 to clear): Raw Status of Interrupt from TPTC A0. Set irrespective if the Interupt is masked or unmasked in MSS_TPCC_A_INTAGG_MASK
  [n+1] tpcc_a_int{n} (n=1..7) — Rising Edge Capture reg (write 1 to clear): Raw Status of Interrupt from MSS_TPCC_A. Set irrespective if the Interupt is masked or unmasked in MSS_TPCC_C_INTAGG_MASK
  [1] tpcc_a_int0 — Rising Edge Capture reg (write 1 to clear): Raw Status of Interrupt from TPCC A. Set irrespective if the Interupt is masked or unmasked in MSS_TPCC_A_INTAGG_MASK
  [0] tpcc_a_intg — Rising Edge Capture reg (write 1 to clear): Raw Status of Interrupt from MSS_TPCC_A. Set irrespective if the Interupt is masked or unmasked in MSS_TPCC_C_INTAGG_MASK
0x188 MSS_TPCC_B_ERRAGG_MASK
  [25] tptc_b0_read_access_error — Mask Error from MSS_TPTC_B0 to aggregated Error MSS_TPCC_B_ERRAGG 1 : Error is Masked 0 : Error is Unmasked
  [24] tpcc_b_read_access_error — Mask Error from MSS_TPCC_B to aggregated Error MSS_TPCC_B_ERRAGG 1 : Error is Masked 0 : Error is Unmasked
  [17] tptc_b0_write_access_error — Mask Error from MSS_TPTC_B0 to aggregated Error MSS_TPCC_B_ERRAGG 1 : Error is Masked 0 : Error is Unmasked
  [16] tpcc_b_write_access_error — Mask Error from MSS_TPCC_B to aggregated Error MSS_TPCC_B_ERRAGG 1 : Error is Masked 0 : Error is Unmasked
  [4] tpcc_b_par_err — Mask Error from MSS_TPCC_B to aggregated Error MSS_TPCC_B_ERRAGG 1 : Error is Masked 0 : Error is Unmasked
  [2] tptc_b0_err — Mask Error from MSS_TPTC_B0 to aggregated Error MSS_TPCC_B_ERRAGG 1 : Error is Masked 0 : Error is Unmasked
  [1] tpcc_b_mpint — Mask Error from MSS_TPCC_B to aggregated Error MSS_TPCC_B_ERRAGG 1 : Error is Masked 0 : Error is Unmasked
  [0] tpcc_b_errint — Mask Error from MSS_TPCC_B to aggregated Error MSS_TPCC_B_ERRAGG 1 : Error is Masked 0 : Error is Unmasked
0x18C MSS_TPCC_B_ERRAGG_STATUS
  [25] tptc_b0_read_access_error — Rising Edge Capture reg (write 1 to clear): Status of Error from MSS_TPTC_B0. Set only if Interupt is unmasked in MSS_TPCC_B_ERRAGG_MASK Wrie 0x1 to clear this Error.
  [24] tpcc_b_read_access_error — Rising Edge Capture reg (write 1 to clear): Status of Error from MSS_TPCC_B. Set only if Interupt is unmasked in MSS_TPCC_B_ERRAGG_MASK Wrie 0x1 to clear this Error.
  [17] tptc_b0_write_access_error — Rising Edge Capture reg (write 1 to clear): Status of Error from MSS_TPTC_B0. Set only if Interupt is unmasked in MSS_TPCC_B_ERRAGG_MASK Wrie 0x1 to clear this Error.
  [16] tpcc_b_write_access_error — Rising Edge Capture reg (write 1 to clear): Status of Error from MSS_TPCC_B. Set only if Interupt is unmasked in MSS_TPCC_B_ERRAGG_MASK Wrie 0x1 to clear this Error.
  [4] tpcc_b_par_err — Rising Edge Capture reg (write 1 to clear): Status of Error from MSS_TPCC_B. Set only if Interupt is unmasked in MSS_TPCC_B_ERRAGG_MASK Wrie 0x1 to clear this Error.
  [2] tptc_b0_err — Rising Edge Capture reg (write 1 to clear): Status of Error from MSS_TPTC_B0. Set only if Interupt is unmasked in MSS_TPCC_B_ERRAGG_MASK Wrie 0x1 to clear this Error.
  [1] tpcc_b_mpint — Rising Edge Capture reg (write 1 to clear): Status of Error from MSS_TPCC_B. Set only if Interupt is unmasked in MSS_TPCC_B_ERRAGG_MASK Wrie 0x1 to clear this Error.
  [0] tpcc_b_errint — Rising Edge Capture reg (write 1 to clear): Status of Error from MSS_TPCC_B. Set only if Interupt is unmasked in MSS_TPCC_B_ERRAGG_MASK Wrie 0x1 to clear this Error.
